# STM32L053C6T6 register map
File version: 1.0
Registers are 32-bit, access not given, reset 0x0 unless marked. A register's access mark holds for its fields unless they carry their own. Offsets are from the block's base; [hi:lo] are bit positions; {n}, {i} and the like mark numbered series.

## LPTIM1
Base 0x40007C00
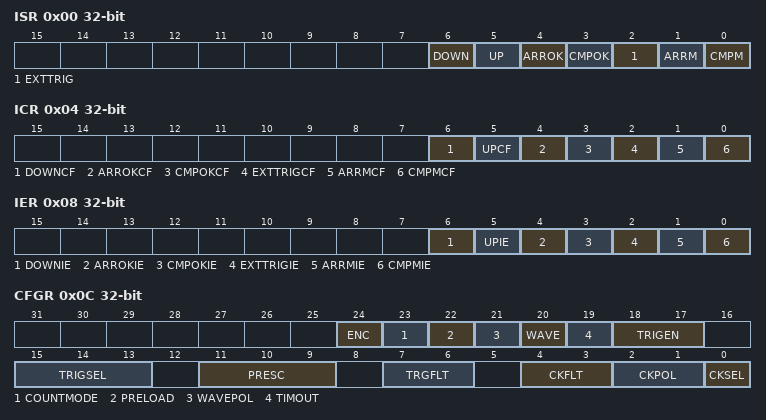
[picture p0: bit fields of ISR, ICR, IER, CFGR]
0x00 ISR
  [6] DOWN, [5] UP, [4] ARROK, [3] CMPOK, [2] EXTTRIG, [1] ARRM, [0] CMPM
0x04 ICR
  [6] DOWNCF, [5] UPCF, [4] ARROKCF, [3] CMPOKCF, [2] EXTTRIGCF, [1] ARRMCF, [0] CMPMCF
0x08 IER
  [6] DOWNIE, [5] UPIE, [4] ARROKIE, [3] CMPOKIE, [2] EXTTRIGIE, [1] ARRMIE, [0] CMPMIE
0x0C CFGR
  [24] ENC, [23] COUNTMODE, [22] PRELOAD, [21] WAVEPOL, [20] WAVE, [19] TIMOUT, [18:17] TRIGEN, [15:13] TRIGSEL, [11:9] PRESC, [7:6] TRGFLT, [4:3] CKFLT, [2:1] CKPOL, [0] CKSEL
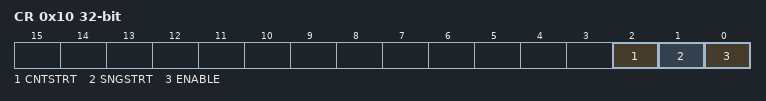
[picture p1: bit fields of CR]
0x10 CR
  [2] CNTSTRT, [1] SNGSTRT, [0] ENABLE
0x14 CMP
  [15:0] CMP
0x18 ARR
  [15:0] ARR
0x1C CNT
  [15:0] CNT

## COMP
Base 0x40010000
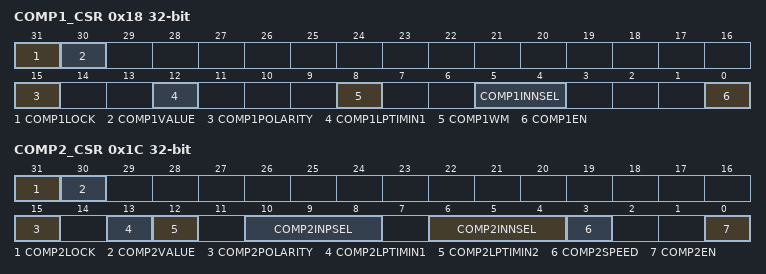
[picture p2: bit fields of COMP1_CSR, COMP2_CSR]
0x18 COMP1_CSR
  [31] COMP1LOCK, [30] COMP1VALUE, [15] COMP1POLARITY, [12] COMP1LPTIMIN1, [8] COMP1WM, [5:4] COMP1INNSEL, [0] COMP1EN
0x1C COMP2_CSR
  [31] COMP2LOCK, [30] COMP2VALUE, [15] COMP2POLARITY, [13] COMP2LPTIMIN1, [12] COMP2LPTIMIN2, [10:8] COMP2INPSEL, [6:4] COMP2INNSEL, [3] COMP2SPEED, [0] COMP2EN

## SYSCFG
Base 0x40010000
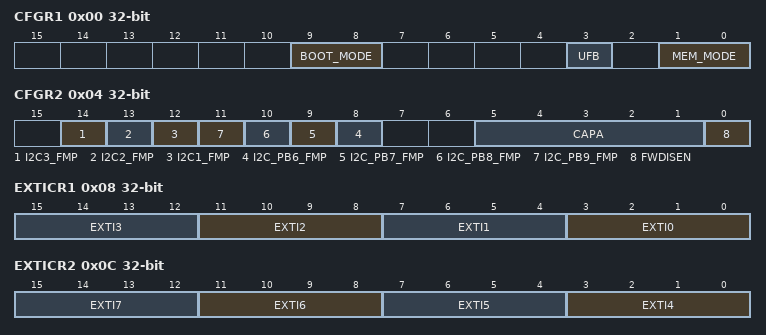
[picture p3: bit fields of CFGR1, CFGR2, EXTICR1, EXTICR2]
0x00 CFGR1
  [9:8] BOOT_MODE, [3] UFB, [1:0] MEM_MODE
0x04 CFGR2
  [14] I2C3_FMP, [13] I2C2_FMP, [12] I2C1_FMP, [n+2] I2C_PB{n}_FMP (n=6..9), [5:1] CAPA, [0] FWDISEN
0x08 EXTICR1
  [4n+3:4n] EXTI{n} (n=0..3)
0x0C EXTICR2
  [4n-13:4n-16] EXTI{n} (n=4..7)
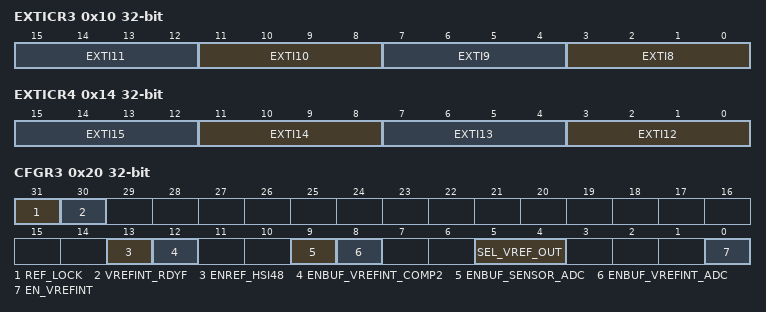
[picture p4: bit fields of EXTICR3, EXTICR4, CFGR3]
0x10 EXTICR3
  [4n-29:4n-32] EXTI{n} (n=8..11)
0x14 EXTICR4
  [4n-45:4n-48] EXTI{n} (n=12..15)
0x20 CFGR3
  [31] REF_LOCK, [30] VREFINT_RDYF, [13] ENREF_HSI48, [12] ENBUF_VREFINT_COMP2, [9] ENBUF_SENSOR_ADC, [8] ENBUF_VREFINT_ADC, [5:4] SEL_VREF_OUT, [0] EN_VREFINT

## EXTI
Base 0x40010400
0x00 IMR
  [29:0] IM
0x04 EMR
  [29:0] EM
0x08 RTSR
  [22:0] RT
0x0C FTSR
  [22:0] FT
0x10 SWIER
  [22:0] SWI
0x14 PR
  [22:0] PIF

## TIM21
Base 0x40010800
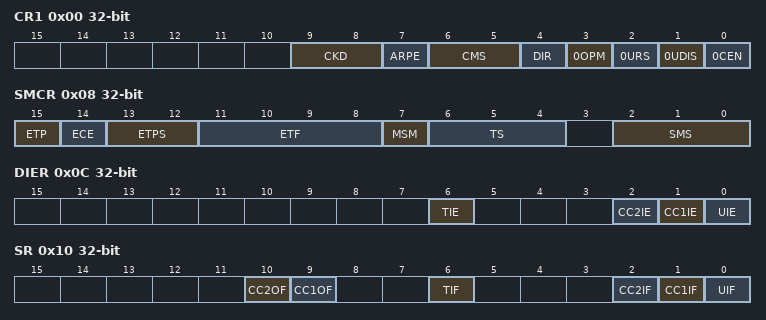
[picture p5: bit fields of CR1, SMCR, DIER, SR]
0x00 CR1
  [9:8] CKD, [7] ARPE, [6:5] CMS, [4] DIR, [3] 0OPM, [2] 0URS, [1] 0UDIS, [0] 0CEN
0x04 CR2
  [6:4] MMS
0x08 SMCR
  [15] ETP, [14] ECE, [13:12] ETPS, [11:8] ETF, [7] MSM, [6:4] TS, [2:0] SMS
0x0C DIER
  [6] TIE, [2] CC2IE, [1] CC1IE, [0] UIE
0x10 SR
  [10] CC2OF, [9] CC1OF, [6] TIF, [2] CC2IF, [1] CC1IF, [0] UIF
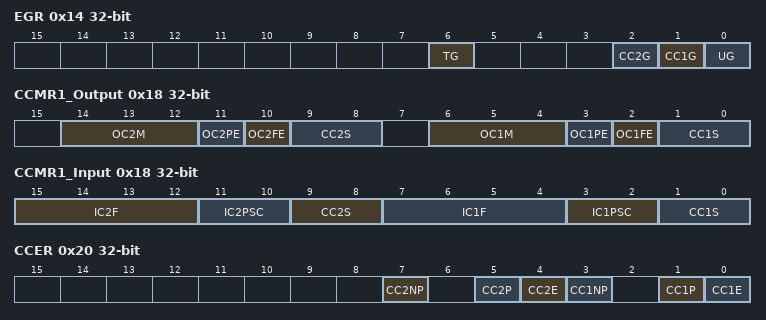
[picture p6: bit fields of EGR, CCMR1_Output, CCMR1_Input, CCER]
0x14 EGR
  [6] TG, [2] CC2G, [1] CC1G, [0] UG
0x18 CCMR1_Output
  [14:12] OC2M, [11] OC2PE, [10] OC2FE, [9:8] CC2S, [6:4] OC1M, [3] OC1PE, [2] OC1FE, [1:0] CC1S
0x18 CCMR1_Input
  [15:12] IC2F, [11:10] IC2PSC, [9:8] CC2S, [7:4] IC1F, [3:2] IC1PSC, [1:0] CC1S
0x20 CCER
  [7] CC2NP, [5] CC2P, [4] CC2E, [3] CC1NP, [1] CC1P, [0] CC1E
0x24 CNT
  [15:0] CNT
0x28 PSC
  [15:0] PSC
0x2C ARR
  [15:0] ARR
0x34 CCR1
  [15:0] CCR1
0x38 CCR2
  [15:0] CCR2
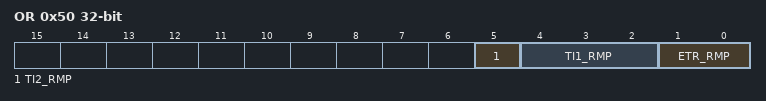
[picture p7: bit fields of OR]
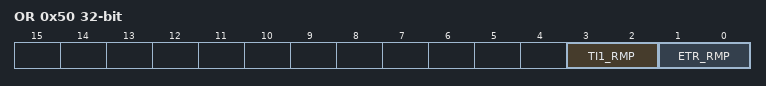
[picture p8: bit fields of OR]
0x50 OR
  [5] TI2_RMP, [4:2] TI1_RMP, [1:0] ETR_RMP

## TIM22
Base 0x40011400
Registers as TIM21; these are added or differ:
0x50 OR
  [3:2] TI1_RMP, [1:0] ETR_RMP

## FW
Base 0x40011C00
0x00 CSSA
  [23:8] ADD
0x04 CSL
  [21:8] LENG
0x08 NVDSSA
  [23:8] ADD
0x0C NVDSL
  [21:8] LENG
0x10 VDSSA
  [15:6] ADD
0x14 VDSL
  [15:6] LENG
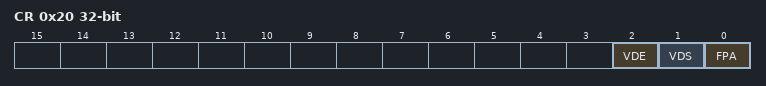
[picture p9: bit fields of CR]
0x20 CR
  [2] VDE, [1] VDS, [0] FPA

## ADC1
Base 0x40012400
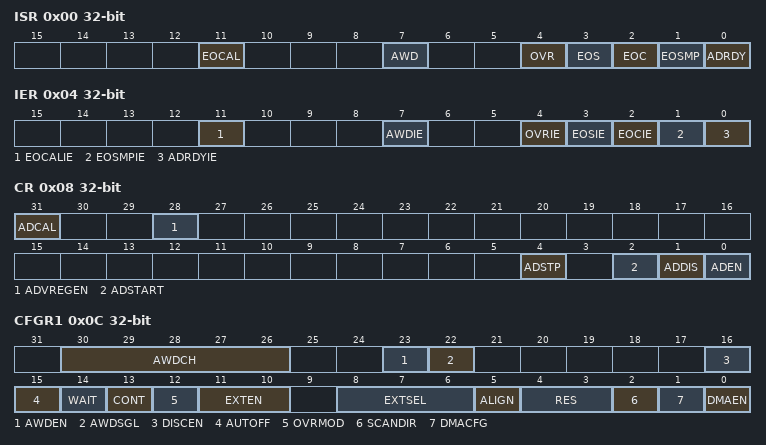
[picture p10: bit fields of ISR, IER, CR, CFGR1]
0x00 ISR
  [11] EOCAL, [7] AWD, [4] OVR, [3] EOS, [2] EOC, [1] EOSMP, [0] ADRDY
0x04 IER
  [11] EOCALIE, [7] AWDIE, [4] OVRIE, [3] EOSIE, [2] EOCIE, [1] EOSMPIE, [0] ADRDYIE
0x08 CR
  [31] ADCAL, [28] ADVREGEN, [4] ADSTP, [2] ADSTART, [1] ADDIS, [0] ADEN
0x0C CFGR1
  [30:26] AWDCH, [23] AWDEN, [22] AWDSGL, [16] DISCEN, [15] AUTOFF, [14] WAIT, [13] CONT, [12] OVRMOD, [11:10] EXTEN, [8:6] EXTSEL, [5] ALIGN, [4:3] RES, [2] SCANDIR, [1] DMACFG, [0] DMAEN
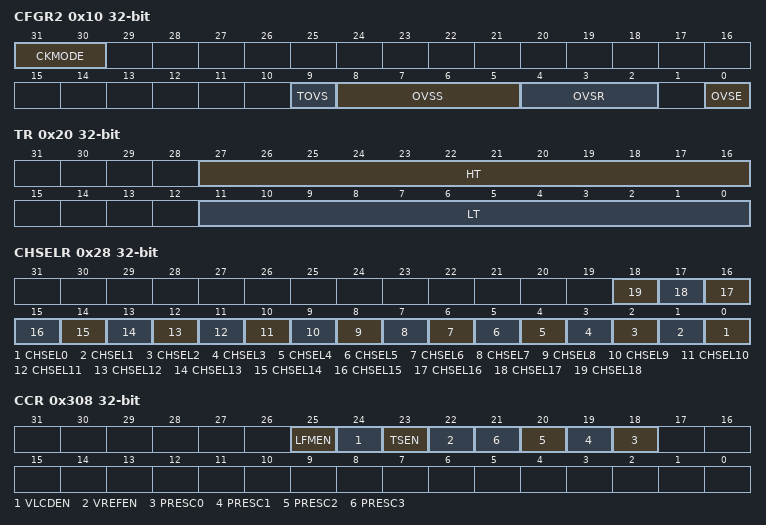
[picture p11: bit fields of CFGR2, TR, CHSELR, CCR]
0x10 CFGR2
  [31:30] CKMODE, [9] TOVS, [8:5] OVSS, [4:2] OVSR, [0] OVSE
0x14 SMPR
  [2:0] SMP
0x20 TR
  [27:16] HT, [11:0] LT
0x28 CHSELR
  [n] CHSEL{n} (n=0..18)
0x40 DR
  [15:0] DATA
0xB4 CALFACT
  [6:0] CALFACT
0x308 CCR
  [25] LFMEN, [24] VLCDEN, [23] TSEN, [22] VREFEN, [n+18] PRESC{n} (n=0..3)
